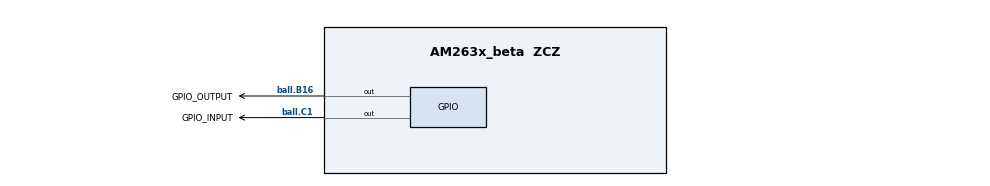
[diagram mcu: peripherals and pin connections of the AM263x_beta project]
/**
 * @cliArgs --device "AM263x_beta" --package "ZCZ" --part "AM263x" --context "r5fss0-0" --product "MCU_PLUS_SDK@07.03.01"
 * @versions {"tool":"1.13.0+2553"}
 */

/**
 * Import the modules used in this configuration.
 */
const epwm       = scripting.addModule("/drivers/epwm/epwm", {}, false);
const epwm1      = epwm.addInstance();
const gpio       = scripting.addModule("/drivers/gpio/gpio", {}, false);
const gpio1      = gpio.addInstance();
const gpio2      = gpio.addInstance();
const debug_log  = scripting.addModule("/kernel/dpl/debug_log");
const mpu_armv7  = scripting.addModule("/kernel/dpl/mpu_armv7", {}, false);
const mpu_armv71 = mpu_armv7.addInstance();
const mpu_armv72 = mpu_armv7.addInstance();
const mpu_armv73 = mpu_armv7.addInstance();
const mpu_armv74 = mpu_armv7.addInstance();
const epwm_xbar  = scripting.addModule("/xbar/epwm_xbar/epwm_xbar", {}, false);
const epwm_xbar1 = epwm_xbar.addInstance();
const int_xbar   = scripting.addModule("/xbar/int_xbar/int_xbar", {}, false);
const int_xbar1  = int_xbar.addInstance();

/**
 * Write custom configuration values to the imported modules.
 */
epwm1.epwmTimebase_emulationMode                                      = "EPWM_EMULATION_FREE_RUN";
epwm1.epwmTimebase_period                                             = 12000;
epwm1.epwmTimebase_counterMode                                        = "EPWM_COUNTER_MODE_UP_DOWN";
epwm1.epwmTimebase_clockDiv                                           = "EPWM_CLOCK_DIVIDER_4";
epwm1.epwmTimebase_hsClockDiv                                         = "EPWM_HSCLOCK_DIVIDER_4";
epwm1.epwmCounterCompare_cmpA                                         = 2000;
epwm1.epwmActionQualifier_EPWM_AQ_OUTPUT_A_ON_TIMEBASE_UP_CMPA        = "EPWM_AQ_OUTPUT_HIGH";
epwm1.epwmActionQualifier_EPWM_AQ_OUTPUT_A_ON_TIMEBASE_DOWN_CMPA      = "EPWM_AQ_OUTPUT_LOW";
epwm1.epwmActionQualifier_EPWM_AQ_OUTPUT_B_ON_TIMEBASE_UP_CMPA        = "EPWM_AQ_OUTPUT_HIGH";
epwm1.epwmActionQualifier_EPWM_AQ_OUTPUT_B_ON_TIMEBASE_DOWN_CMPA      = "EPWM_AQ_OUTPUT_LOW";
epwm1.epwmActionQualifier_EPWM_AQ_OUTPUT_B_usedEvents                 = ["EPWM_AQ_OUTPUT_ON_TIMEBASE_DOWN_CMPA","EPWM_AQ_OUTPUT_ON_TIMEBASE_UP_CMPA"];
epwm1.epwmActionQualifier_EPWM_AQ_OUTPUT_A_usedEvents                 = ["EPWM_AQ_OUTPUT_ON_TIMEBASE_DOWN_CMPA","EPWM_AQ_OUTPUT_ON_TIMEBASE_UP_CMPA"];
epwm1.epwmEventTrigger_enableInterrupt                                = true;
epwm1.epwmEventTrigger_interruptEventCount                            = "1";
epwm1.epwmDigitalCompare_EPWM_DC_MODULE_A_EPWM_DC_EVENT_1_eventSync   = "EPWM_DC_EVENT_INPUT_NOT_SYNCED";
epwm1.epwmDigitalCompare_EPWM_DC_MODULE_B_EPWM_DC_EVENT_1_eventSource = "EPWM_DC_EVENT_SOURCE_FILT_SIGNAL";
epwm1.epwmDigitalCompare_dcFilterInput                                = "EPWM_DC_WINDOW_SOURCE_DCBEVT1";
epwm1.epwmDigitalCompare_useEdgeFilter                                = true;
epwm1.epwmDigitalCompare_enableValleyCapture                          = true;
epwm1.epwmDigitalCompare_enableEdgeFilterDelay                        = true;
epwm1.epwmDigitalCompare_SWVDELVAL                                    = 3000;
epwm1.epwmDigitalCompare_valleyCaptureSource                          = "EPWM_VALLEY_TRIGGER_EVENT_CNTR_ZERO";
epwm1.epwmTripZone_oneShotSource                                      = ["EPWM_TZ_SIGNAL_DCBEVT1"];
epwm1.epwmDigitalCompare_EPWM_DC_MODULE_B_EPWM_DC_EVENT_1_eventSync   = "EPWM_DC_EVENT_INPUT_NOT_SYNCED";
epwm1.epwmTripZone_EPWM_TZ_ACTION_EVENT_TZA                           = "EPWM_TZ_ACTION_LOW";
epwm1.epwmTripZone_EPWM_TZ_ACTION_EVENT_TZB                           = "EPWM_TZ_ACTION_LOW";
epwm1.epwmDigitalCompare_EPWM_TZ_DC_OUTPUT_A1                         = "EPWM_TZ_EVENT_DCXH_LOW";
epwm1.epwmDigitalCompare_EPWM_TZ_DC_OUTPUT_B1                         = "EPWM_TZ_EVENT_DCXH_LOW";
epwm1.epwmTripZone_EPWM_TZ_ACTION_EVENT_DCAEVT1                       = "EPWM_TZ_ACTION_LOW";
epwm1.$name                                                           = "CONFIG_EPWMx";
epwm1.EPWM.$assign                                                    = "EPWM0";

gpio1.pinDir               = "OUTPUT";
gpio1.$name                = "GPIO_OUTPUT";
gpio1.GPIO.$assign         = "GPIO0";
gpio1.GPIO.gpioPin.$assign = "ball.B16";

gpio2.$name                = "GPIO_INPUT";
gpio2.GPIO.gpioPin.$assign = "ball.C1";

debug_log.enableUartLog            = true;
debug_log.uartLog.$name            = "CONFIG_UART0";
debug_log.uartLog.UART.RXD.$assign = "ball.A7";
debug_log.uartLog.UART.TXD.$assign = "ball.A6";

mpu_armv71.$name             = "CONFIG_MPU_REGION0";
mpu_armv71.size              = 31;
mpu_armv71.attributes        = "Device";
mpu_armv71.accessPermissions = "Supervisor RD+WR, User RD";
mpu_armv71.allowExecute      = false;

mpu_armv72.$name             = "CONFIG_MPU_REGION1";
mpu_armv72.size              = 15;
mpu_armv72.accessPermissions = "Supervisor RD+WR, User RD";

mpu_armv73.$name             = "CONFIG_MPU_REGION2";
mpu_armv73.baseAddr          = 0x80000;
mpu_armv73.size              = 15;
mpu_armv73.accessPermissions = "Supervisor RD+WR, User RD";

mpu_armv74.$name             = "CONFIG_MPU_REGION3";
mpu_armv74.accessPermissions = "Supervisor RD+WR, User RD";
mpu_armv74.baseAddr          = 0x70000000;
mpu_armv74.size              = 21;

epwm_xbar1.$name                 = "CONFIG_EPWM_XBAR0";
epwm_xbar1.xbarOutput            = ["GPIO48"];
epwm_xbar1["xbarConfig-0"].$name = "CONFIG_INPUT_XBAR0";

int_xbar1.$name      = "CONFIG_INT_XBAR0";
int_xbar1.xbarOutput = ["EPWM0_INT"];

/**
 * Pinmux solution for unlocked pins/peripherals. This ensures that minor changes to the automatic solver in a future
 * version of the tool will not impact the pinmux you originally saw.  These lines can be completely deleted in order to
 * re-solve from scratch.
 */
epwm1.EPWM.A.$suggestSolution           = "ball.B2";
epwm1.EPWM.B.$suggestSolution           = "ball.B1";
gpio2.GPIO.$suggestSolution             = "GPIO0";
debug_log.uartLog.UART.$suggestSolution = "UART0";
